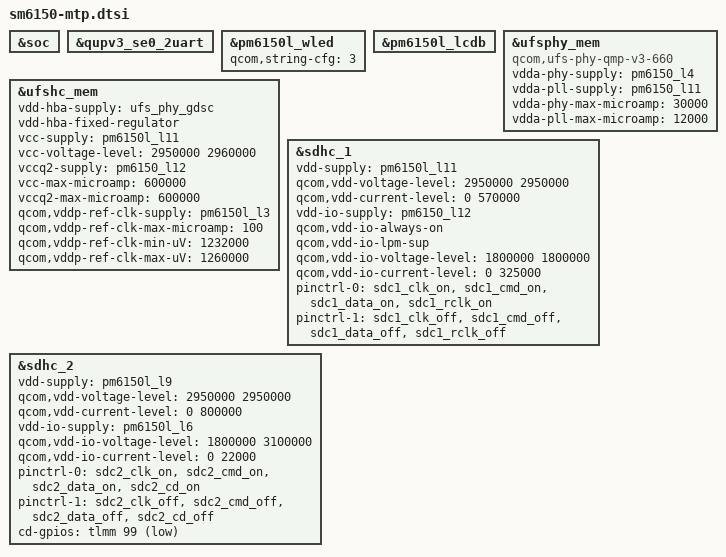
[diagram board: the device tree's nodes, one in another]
/* Copyright (c) 2018, The Linux Foundation. All rights reserved.
 *
 * This program is free software; you can redistribute it and/or modify
 * it under the terms of the GNU General Public License version 2 and
 * only version 2 as published by the Free Software Foundation.
 *
 * This program is distributed in the hope that it will be useful,
 * but WITHOUT ANY WARRANTY; without even the implied warranty of
 * MERCHANTABILITY or FITNESS FOR A PARTICULAR PURPOSE.  See the
 * GNU General Public License for more details.
 */

#include "sm6150-thermal-overlay.dtsi"

&soc {
};

&qupv3_se0_2uart {
	status = "ok";
};

&pm6150l_wled {
	qcom,string-cfg= <3>;
	status = "ok";
};

&pm6150l_lcdb {
	status = "ok";
};

&ufsphy_mem {
	compatible = "qcom,ufs-phy-qmp-v3-660";

	vdda-phy-supply = <&pm6150_l4>; /* 0.9v */
	vdda-pll-supply = <&pm6150_l11>;
	vdda-phy-max-microamp = <30000>;
	vdda-pll-max-microamp = <12000>;

	status = "ok";
};

&ufshc_mem {
	vdd-hba-supply = <&ufs_phy_gdsc>;
	vdd-hba-fixed-regulator;
	vcc-supply = <&pm6150l_l11>;
	vcc-voltage-level = <2950000 2960000>;
	vccq2-supply = <&pm6150_l12>;
	vcc-max-microamp = <600000>;
	vccq2-max-microamp = <600000>;

	qcom,vddp-ref-clk-supply = <&pm6150l_l3>;
	qcom,vddp-ref-clk-max-microamp = <100>;
	qcom,vddp-ref-clk-min-uV = <1232000>;
	qcom,vddp-ref-clk-max-uV = <1260000>;

	status = "ok";
};

&sdhc_1 {
	vdd-supply = <&pm6150l_l11>;
	qcom,vdd-voltage-level = <2950000 2950000>;
	qcom,vdd-current-level = <0 570000>;

	vdd-io-supply = <&pm6150_l12>;
	qcom,vdd-io-always-on;
	qcom,vdd-io-lpm-sup;
	qcom,vdd-io-voltage-level = <1800000 1800000>;
	qcom,vdd-io-current-level = <0 325000>;

	pinctrl-names = "active", "sleep";
	pinctrl-0 = <&sdc1_clk_on &sdc1_cmd_on &sdc1_data_on &sdc1_rclk_on>;
	pinctrl-1 = <&sdc1_clk_off &sdc1_cmd_off &sdc1_data_off &sdc1_rclk_off>;

	status = "ok";
};

&sdhc_2 {
	vdd-supply = <&pm6150l_l9>;
	qcom,vdd-voltage-level = <2950000 2950000>;
	qcom,vdd-current-level = <0 800000>;

	vdd-io-supply = <&pm6150l_l6>;
	qcom,vdd-io-voltage-level = <1800000 3100000>;
	qcom,vdd-io-current-level = <0 22000>;

	pinctrl-names = "active", "sleep";
	pinctrl-0 = <&sdc2_clk_on  &sdc2_cmd_on &sdc2_data_on &sdc2_cd_on>;
	pinctrl-1 = <&sdc2_clk_off &sdc2_cmd_off &sdc2_data_off &sdc2_cd_off>;

	cd-gpios = <&tlmm 99 1>;

	status = "ok";
};
